# ZB204 register map
Vendor: GS; File version: 1.2
CPU: CM3 r2p0, little endian, MPU, no FPU, VTOR, 3 interrupt priority bits
Registers are 32-bit, read-write, reset 0x0 unless marked. A register's access mark holds for its fields unless they carry their own. Offsets are from the block's base; [hi:lo] are bit positions; {n}, {i} and the like mark numbered series.

## BPLC
Base 0x40500000
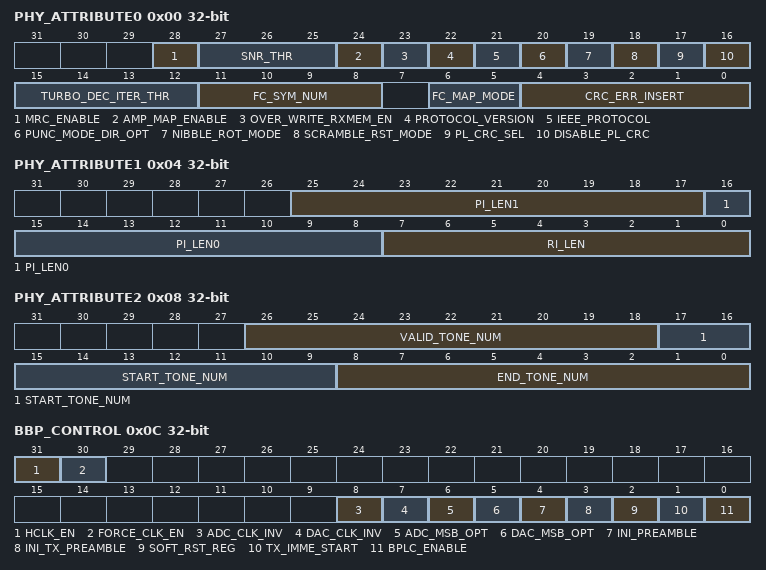
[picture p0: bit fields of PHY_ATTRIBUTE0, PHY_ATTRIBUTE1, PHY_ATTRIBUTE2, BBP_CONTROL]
0x00 PHY_ATTRIBUTE0
  [28] MRC_ENABLE, [27:25] SNR_THR, [24] AMP_MAP_ENABLE, [23] OVER_WRITE_RXMEM_EN, [22] PROTOCOL_VERSION, [21] IEEE_PROTOCOL, [20] PUNC_MODE_DIR_OPT, [19] NIBBLE_ROT_MODE, [18] SCRAMBLE_RST_MODE, [17] PL_CRC_SEL, [16] DISABLE_PL_CRC, [15:12] TURBO_DEC_ITER_THR, [11:8] FC_SYM_NUM, [6:5] FC_MAP_MODE, [4:0] CRC_ERR_INSERT
0x04 PHY_ATTRIBUTE1
  [25:17] PI_LEN1, [16:8] PI_LEN0, [7:0] RI_LEN
0x08 PHY_ATTRIBUTE2
  [26:18] VALID_TONE_NUM, [17:9] START_TONE_NUM, [8:0] END_TONE_NUM
0x0C BBP_CONTROL
  [31] HCLK_EN, [30] FORCE_CLK_EN, [8] ADC_CLK_INV, [7] DAC_CLK_INV, [6] ADC_MSB_OPT, [5] DAC_MSB_OPT, [4] INI_PREAMBLE, [3] INI_TX_PREAMBLE, [2] SOFT_RST_REG, [1] TX_IMME_START, [0] BPLC_ENABLE
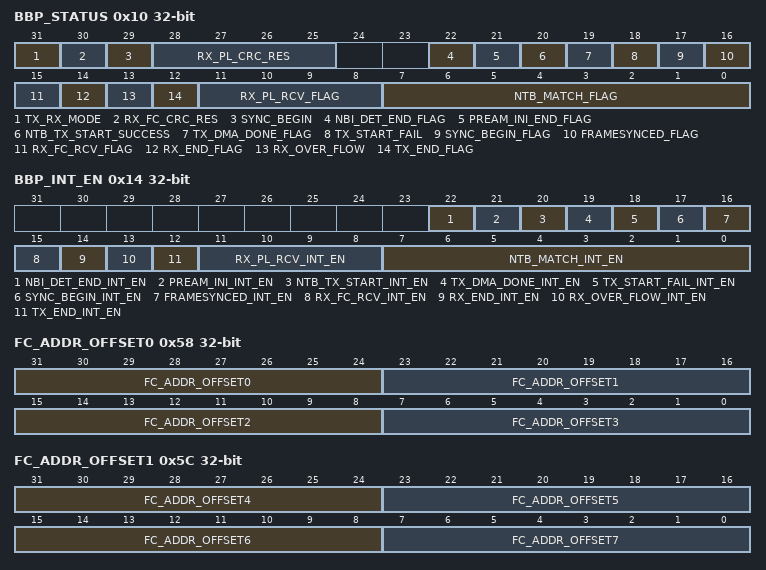
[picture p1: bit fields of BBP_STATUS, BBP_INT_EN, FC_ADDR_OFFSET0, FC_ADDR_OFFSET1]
0x10 BBP_STATUS
  [31] TX_RX_MODE, [30] RX_FC_CRC_RES, [29] SYNC_BEGIN, [28:25] RX_PL_CRC_RES, [22] NBI_DET_END_FLAG, [21] PREAM_INI_END_FLAG, [20] NTB_TX_START_SUCCESS, [19] TX_DMA_DONE_FLAG, [18] TX_START_FAIL, [17] SYNC_BEGIN_FLAG, [16] FRAMESYNCED_FLAG, [15] RX_FC_RCV_FLAG, [14] RX_END_FLAG, [13] RX_OVER_FLOW, [12] TX_END_FLAG, [11:8] RX_PL_RCV_FLAG, [7:0] NTB_MATCH_FLAG
0x14 BBP_INT_EN
  [22] NBI_DET_END_INT_EN, [21] PREAM_INI_INT_EN, [20] NTB_TX_START_INT_EN, [19] TX_DMA_DONE_INT_EN, [18] TX_START_FAIL_INT_EN, [17] SYNC_BEGIN_INT_EN, [16] FRAMESYNCED_INT_EN, [15] RX_FC_RCV_INT_EN, [14] RX_END_INT_EN, [13] RX_OVER_FLOW_INT_EN, [12] TX_END_INT_EN, [11:8] RX_PL_RCV_INT_EN, [7:0] NTB_MATCH_INT_EN
{0x18+4i} TONEMASKTABLE[{i}] (i=0..15) — tone_mask_tab0
  [31:0] TONE_MASK_TAB0
0x58 FC_ADDR_OFFSET0
  [31-8n:24-8n] FC_ADDR_OFFSET{n} (n=0..3)
0x5C FC_ADDR_OFFSET1
  [63-8n:56-8n] FC_ADDR_OFFSET{n} (n=4..7)
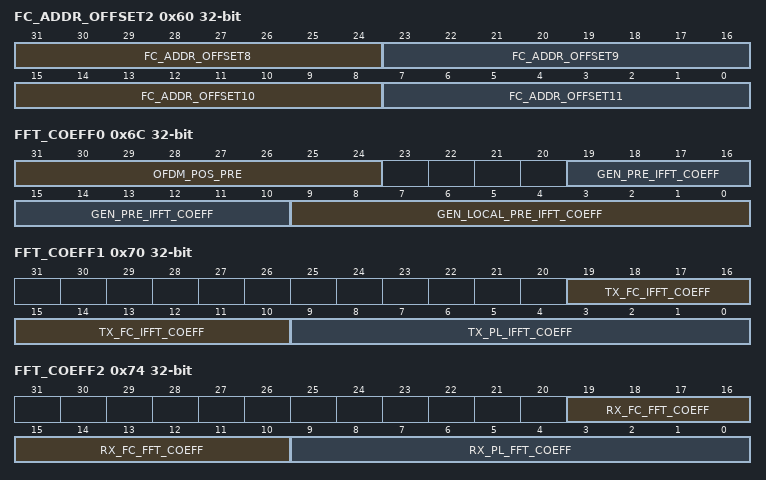
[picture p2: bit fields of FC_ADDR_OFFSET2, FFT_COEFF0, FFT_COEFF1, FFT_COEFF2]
0x60 FC_ADDR_OFFSET2
  [95-8n:88-8n] FC_ADDR_OFFSET{n} (n=8..11)
0x64 ENCRYPT0
  [31:0] ENCRYPT_CODE0
0x68 ENCRYPT1
  [31:0] ENCRYPT_CODE1
0x6C FFT_COEFF0
  [31:24] OFDM_POS_PRE, [19:10] GEN_PRE_IFFT_COEFF, [9:0] GEN_LOCAL_PRE_IFFT_COEFF
0x70 FFT_COEFF1
  [19:10] TX_FC_IFFT_COEFF, [9:0] TX_PL_IFFT_COEFF
0x74 FFT_COEFF2
  [19:10] RX_FC_FFT_COEFF, [9:0] RX_PL_FFT_COEFF
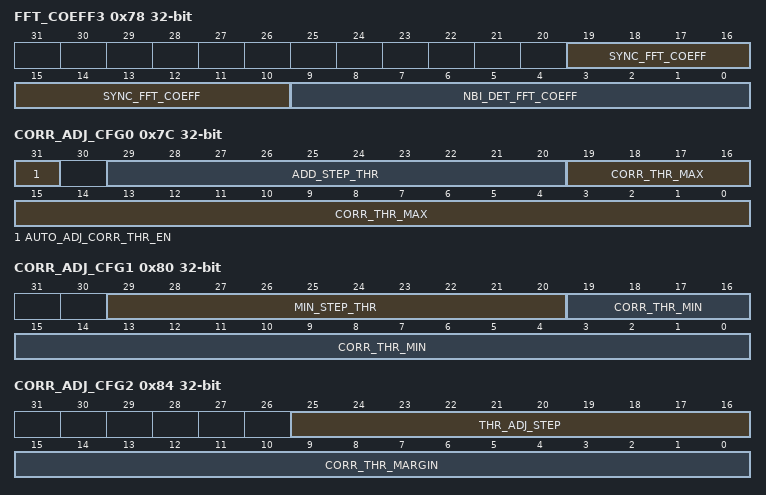
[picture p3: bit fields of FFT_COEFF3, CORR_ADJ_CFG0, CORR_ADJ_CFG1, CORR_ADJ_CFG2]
0x78 FFT_COEFF3
  [19:10] SYNC_FFT_COEFF, [9:0] NBI_DET_FFT_COEFF
0x7C CORR_ADJ_CFG0
  [31] AUTO_ADJ_CORR_THR_EN, [29:20] ADD_STEP_THR, [19:0] CORR_THR_MAX
0x80 CORR_ADJ_CFG1
  [29:20] MIN_STEP_THR, [19:0] CORR_THR_MIN
0x84 CORR_ADJ_CFG2
  [25:16] THR_ADJ_STEP, [15:0] CORR_THR_MARGIN
0x88 CORR_ADJ_CFG3
  [31:0] FSYNC_INTERVAL_CNT
0x8C CORR_ADJ_RES
  [19:0] AUTO_CORR_THR_ADJ_RES
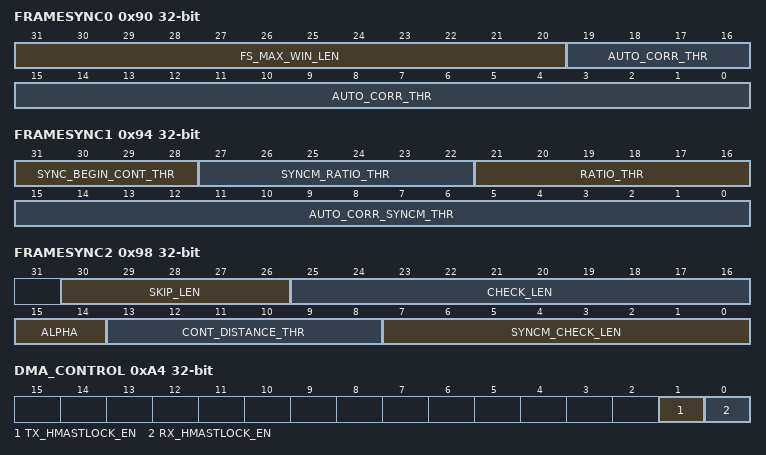
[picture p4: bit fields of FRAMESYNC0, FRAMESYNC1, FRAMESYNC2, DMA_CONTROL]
0x90 FRAMESYNC0
  [31:20] FS_MAX_WIN_LEN, [19:0] AUTO_CORR_THR
0x94 FRAMESYNC1
  [31:28] SYNC_BEGIN_CONT_THR, [27:22] SYNCM_RATIO_THR, [21:16] RATIO_THR, [15:0] AUTO_CORR_SYNCM_THR
0x98 FRAMESYNC2
  [30:26] SKIP_LEN, [25:16] CHECK_LEN, [15:14] ALPHA, [13:8] CONT_DISTANCE_THR, [7:0] SYNCM_CHECK_LEN
0x9C DMA_RX_BADDR
  [31:0] RX_BASE_ADDR
0xA0 DMA_TX_BADDR
  [31:0] TX_BASE_ADDR
0xA4 DMA_CONTROL
  [1] TX_HMASTLOCK_EN, [0] RX_HMASTLOCK_EN
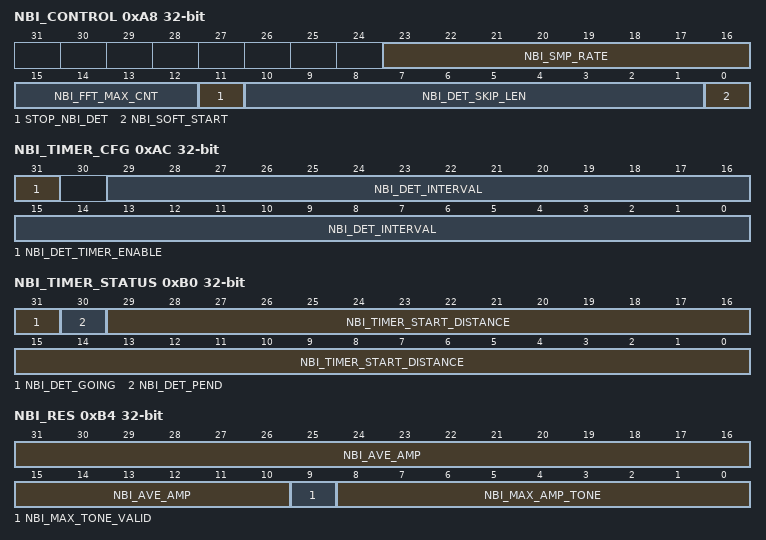
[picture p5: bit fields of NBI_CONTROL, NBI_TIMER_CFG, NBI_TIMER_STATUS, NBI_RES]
0xA8 NBI_CONTROL
  [23:16] NBI_SMP_RATE, [15:12] NBI_FFT_MAX_CNT, [11] STOP_NBI_DET, [10:1] NBI_DET_SKIP_LEN, [0] NBI_SOFT_START
0xAC NBI_TIMER_CFG
  [31] NBI_DET_TIMER_ENABLE, [29:0] NBI_DET_INTERVAL
0xB0 NBI_TIMER_STATUS
  [31] NBI_DET_GOING, [30] NBI_DET_PEND, [29:0] NBI_TIMER_START_DISTANCE
0xB4 NBI_RES
  [31:10] NBI_AVE_AMP, [9] NBI_MAX_TONE_VALID, [8:0] NBI_MAX_AMP_TONE
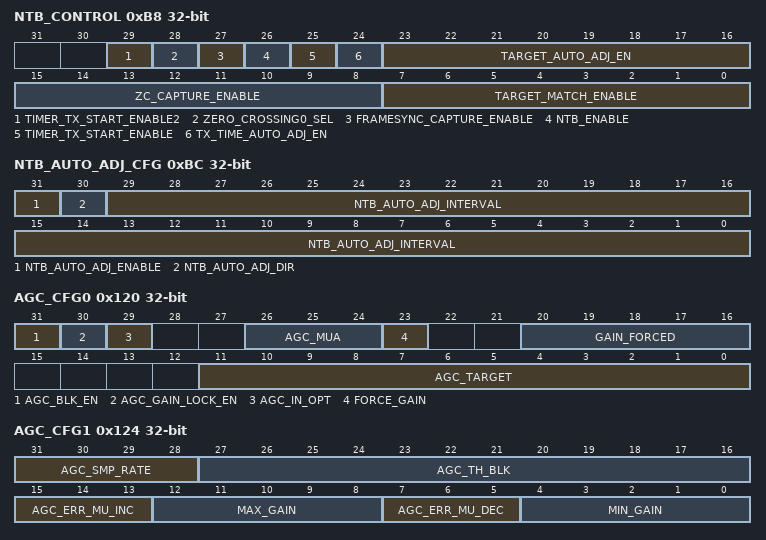
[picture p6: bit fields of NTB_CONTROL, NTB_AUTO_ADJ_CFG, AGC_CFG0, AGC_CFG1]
0xB8 NTB_CONTROL
  [29] TIMER_TX_START_ENABLE2, [28] ZERO_CROSSING0_SEL, [27] FRAMESYNC_CAPTURE_ENABLE, [26] NTB_ENABLE, [25] TIMER_TX_START_ENABLE, [24] TX_TIME_AUTO_ADJ_EN, [23:16] TARGET_AUTO_ADJ_EN, [15:8] ZC_CAPTURE_ENABLE, [7:0] TARGET_MATCH_ENABLE
0xBC NTB_AUTO_ADJ_CFG
  [31] NTB_AUTO_ADJ_ENABLE, [30] NTB_AUTO_ADJ_DIR, [29:0] NTB_AUTO_ADJ_INTERVAL
0xC0 NTB_OFFSET_ADJ
  [31:0] NTB_OFFSET
0xC4 NTB_RELOAD
  [31:0] NTB_RELOAD_VALUE
0xC8 NTB_TX_START_TIME
  [31:0] NTB_TX_START_TARGET
{0xCC+4i} NTB_MATCH_TARGET[{i}] (i=0..7) — NTB_MATCH_TARGET0
  [31:0] TIMER_MATCH_TARGET0 — ntb_match_target0
0xEC NTB_COUNTER_VALUE
  [31:0] NTB_COUNTER_OUT
0xF0 NTB_OFFSET_LATCH
  [31:0] NTB_OFFSET_LATCH_VALUE
0xF4 NTB_FRAMESYNC
{0xF8+4i} NTB_ZERO_CROSSING{i} (i=0..7)
0x118 NONMASK_PWR_SUM
  [24:0] AVE_PWR_SUM
0x11C NONMASK_NOISE_SUM
  [24:0] NOISE_SUM
0x120 AGC_CFG0
  [31] AGC_BLK_EN, [30] AGC_GAIN_LOCK_EN, [29] AGC_IN_OPT, [26:24] AGC_MUA, [23] FORCE_GAIN, [20:16] GAIN_FORCED, [11:0] AGC_TARGET
0x124 AGC_CFG1
  [31:28] AGC_SMP_RATE, [27:16] AGC_TH_BLK, [15:13] AGC_ERR_MU_INC, [12:8] MAX_GAIN, [7:5] AGC_ERR_MU_DEC, [4:0] MIN_GAIN
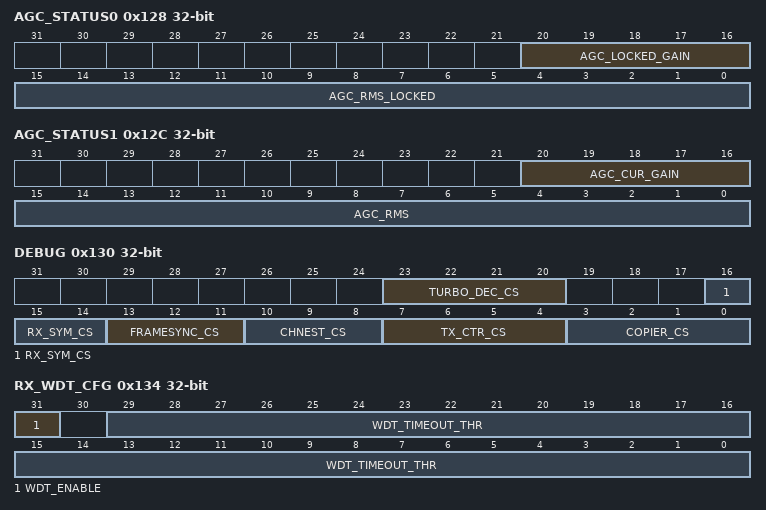
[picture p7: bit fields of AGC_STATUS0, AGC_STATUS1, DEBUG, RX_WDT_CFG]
0x128 AGC_STATUS0
  [20:16] AGC_LOCKED_GAIN, [15:0] AGC_RMS_LOCKED
0x12C AGC_STATUS1
  [20:16] AGC_CUR_GAIN, [15:0] AGC_RMS
0x130 DEBUG
  [23:20] TURBO_DEC_CS, [16:14] RX_SYM_CS, [13:11] FRAMESYNC_CS, [10:8] CHNEST_CS, [7:4] TX_CTR_CS, [3:0] COPIER_CS
0x134 RX_WDT_CFG
  [31] WDT_ENABLE, [29:0] WDT_TIMEOUT_THR
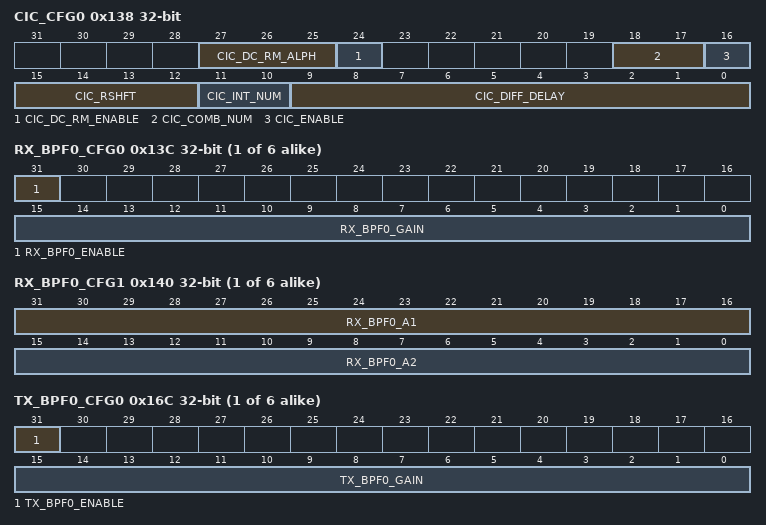
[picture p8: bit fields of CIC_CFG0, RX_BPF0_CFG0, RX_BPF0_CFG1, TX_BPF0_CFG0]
0x138 CIC_CFG0
  [27:25] CIC_DC_RM_ALPH
  [24] CIC_DC_RM_ENABLE
  [18:17] CIC_COMB_NUM — cic_sec_num
  [16] CIC_ENABLE
  [15:12] CIC_RSHFT
  [11:10] CIC_INT_NUM — cic_sec_num
  [9:0] CIC_DIFF_DELAY
{0x13C+8i} RX_BPF{i}_CFG0 (i=0..5)
  [31] RX_BPF{i}_ENABLE, [15:0] RX_BPF{i}_GAIN
{0x140+8i} RX_BPF{i}_CFG1 (i=0..5)
  [31:16] RX_BPF{i}_A1, [15:0] RX_BPF{i}_A2
{0x16C+8i} TX_BPF{i}_CFG0 (i=0..5)
  [31] TX_BPF{i}_ENABLE, [15:0] TX_BPF{i}_GAIN
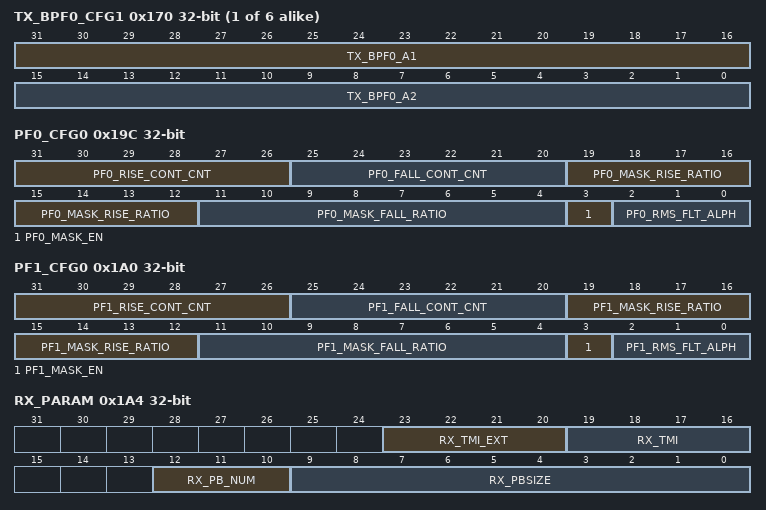
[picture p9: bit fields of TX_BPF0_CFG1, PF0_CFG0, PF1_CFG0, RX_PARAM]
{0x170+8i} TX_BPF{i}_CFG1 (i=0..5)
  [31:16] TX_BPF{i}_A1, [15:0] TX_BPF{i}_A2
0x19C PF0_CFG0
  [31:26] PF0_RISE_CONT_CNT, [25:20] PF0_FALL_CONT_CNT, [19:12] PF0_MASK_RISE_RATIO, [11:4] PF0_MASK_FALL_RATIO, [3] PF0_MASK_EN, [2:0] PF0_RMS_FLT_ALPH
0x1A0 PF1_CFG0
  [31:26] PF1_RISE_CONT_CNT, [25:20] PF1_FALL_CONT_CNT, [19:12] PF1_MASK_RISE_RATIO, [11:4] PF1_MASK_FALL_RATIO, [3] PF1_MASK_EN, [2:0] PF1_RMS_FLT_ALPH
0x1A4 RX_PARAM
  [23:20] RX_TMI_EXT, [19:16] RX_TMI, [12:10] RX_PB_NUM, [9:0] RX_PBSIZE
0x1A8 NTB_TX_START_TIME2
  [31:0] NTB_TX_START_TARGET2
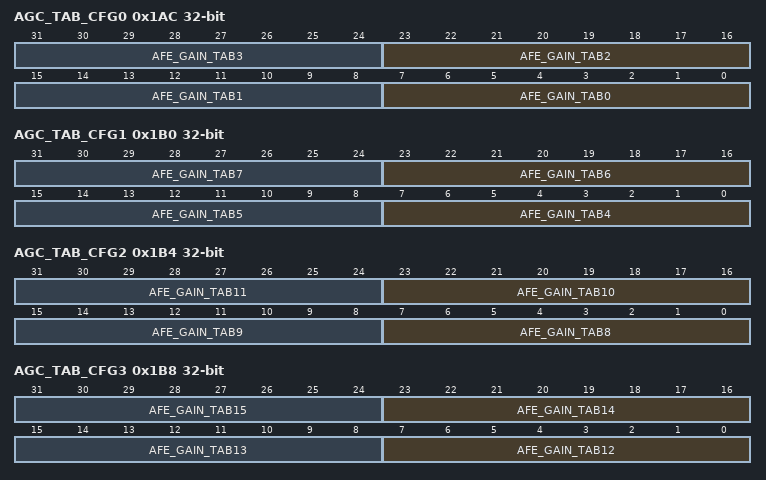
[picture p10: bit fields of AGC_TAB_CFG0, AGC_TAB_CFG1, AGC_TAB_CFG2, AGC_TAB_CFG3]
0x1AC AGC_TAB_CFG0
  [8n+7:8n] AFE_GAIN_TAB{n} (n=0..3)
0x1B0 AGC_TAB_CFG1
  [8n-25:8n-32] AFE_GAIN_TAB{n} (n=4..7)
0x1B4 AGC_TAB_CFG2
  [8n-57:8n-64] AFE_GAIN_TAB{n} (n=8..11)
0x1B8 AGC_TAB_CFG3
  [8n-89:8n-96] AFE_GAIN_TAB{n} (n=12..15)
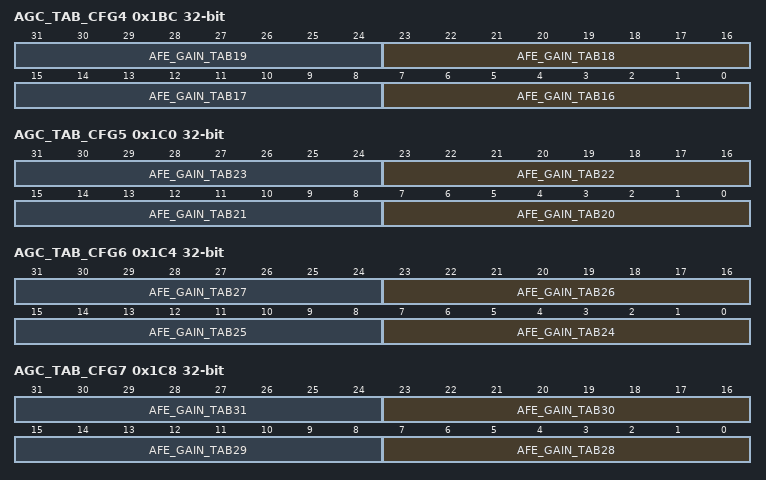
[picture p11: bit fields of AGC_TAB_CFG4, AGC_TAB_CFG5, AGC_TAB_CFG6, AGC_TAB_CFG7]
0x1BC AGC_TAB_CFG4
  [8n-121:8n-128] AFE_GAIN_TAB{n} (n=16..19)
0x1C0 AGC_TAB_CFG5
  [8n-153:8n-160] AFE_GAIN_TAB{n} (n=20..23)
0x1C4 AGC_TAB_CFG6
  [8n-185:8n-192] AFE_GAIN_TAB{n} (n=24..27)
0x1C8 AGC_TAB_CFG7
  [8n-217:8n-224] AFE_GAIN_TAB{n} (n=28..31)
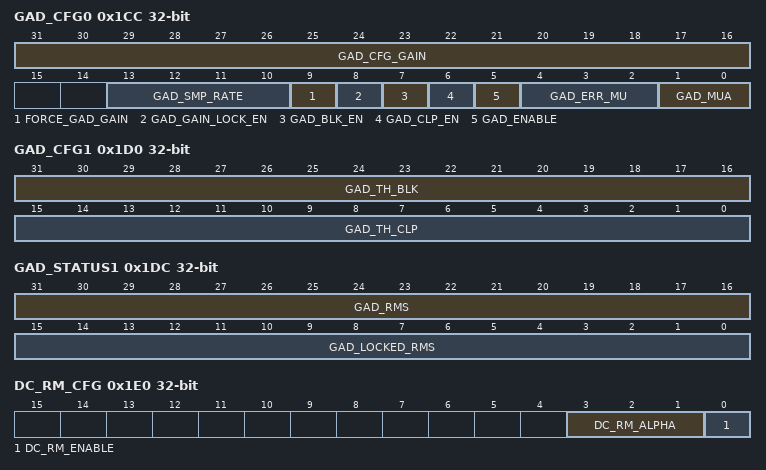
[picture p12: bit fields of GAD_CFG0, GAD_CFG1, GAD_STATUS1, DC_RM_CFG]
0x1CC GAD_CFG0
  [31:16] GAD_CFG_GAIN, [13:10] GAD_SMP_RATE, [9] FORCE_GAD_GAIN, [8] GAD_GAIN_LOCK_EN, [7] GAD_BLK_EN, [6] GAD_CLP_EN, [5] GAD_ENABLE, [4:2] GAD_ERR_MU, [1:0] GAD_MUA
0x1D0 GAD_CFG1
  [31:16] GAD_TH_BLK, [15:0] GAD_TH_CLP
0x1D4 GAD_CFG2
  [15:0] GAD_REF
0x1D8 GAD_STATUS0
  [27:0] GAD_LOCKED_GAIN
0x1DC GAD_STATUS1
  [31:16] GAD_RMS, [15:0] GAD_LOCKED_RMS
0x1E0 DC_RM_CFG
  [3:1] DC_RM_ALPHA, [0] DC_RM_ENABLE
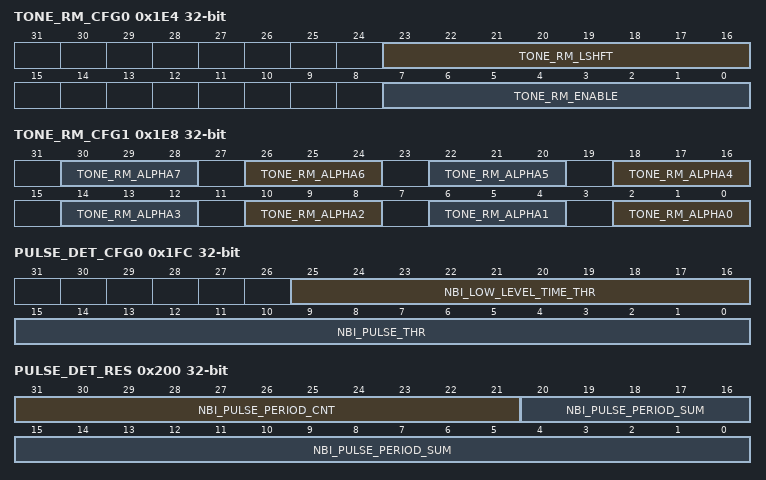
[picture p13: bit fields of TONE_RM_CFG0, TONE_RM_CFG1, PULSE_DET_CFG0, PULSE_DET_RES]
0x1E4 TONE_RM_CFG0
  [23:16] TONE_RM_LSHFT — tone_rm_alpha1
  [7:0] TONE_RM_ENABLE — tone_rm_alpha0
0x1E8 TONE_RM_CFG1
  [4n+2:4n] TONE_RM_ALPHA{n} (n=0..7) — tone_rm_alpha{n+8}
{0x1EC+4i} TONE_RM_FCW[{i}] (i=0..3) — TONE_RM_CFG2
  [31:0] TONE_RM_FCW0 — tone_rm_alpha23
0x1FC PULSE_DET_CFG0
  [25:16] NBI_LOW_LEVEL_TIME_THR, [15:0] NBI_PULSE_THR
0x200 PULSE_DET_RES
  [31:21] NBI_PULSE_PERIOD_CNT, [20:0] NBI_PULSE_PERIOD_SUM
